# M3351 register map
File version: 1.0
Registers are 32-bit, read-write, reset 0x0 unless marked. A register's access mark holds for its fields unless they carry their own. Offsets are from the block's base; [hi:lo] are bit positions; {n}, {i} and the like mark numbered series.

## WWDT0 — WWDT Register Map
Base 0x40096000
Same registers: WWDT1 0x40098000, WWDT1_NS 0x50098000
0x00 WWDT_RLDCNT wo — WWDT Reload Counter Register
  [31:0] RLDCNT — WWDT Reload Counter Register. Writing 0x00005AA5 to this register will reload the WWDT counter value to 0x3F. Note: User can only write WWDT_RLDCNT register to reload WWDT counter value when current WWDT counter value between 0 and CMPDAT (WWDT_CTL[21:16]). If user writes WWDT_RLDCNT when current WWDT counter value is larger than CMPDAT, WWDT reset signal will be generated immediately.
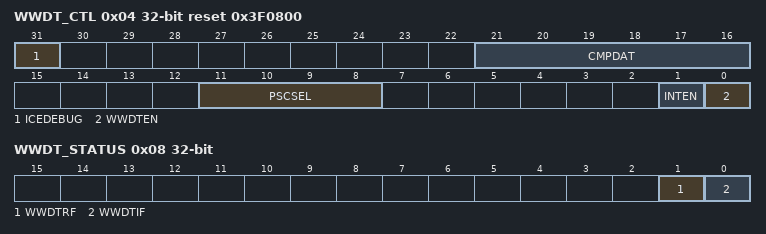
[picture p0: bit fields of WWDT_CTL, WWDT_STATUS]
0x04 WWDT_CTL reset 0x3F0800 — WWDT Control Register
  [31] ICEDEBUG — ICE Debug Mode Acknowledge Disable Bit. WWDT down counter will keep going no matter CPU is held by ICE or not.
    0=ICE debug mode acknowledgement effects WWDT counting; 1=ICE debug mode acknowledgement Disabled
  [21:16] CMPDAT — WWDT Window Compare. Set this register to adjust the valid reload window. Note: User can only write WWDT_RLDCNT register to reload WWDT counter value when current WWDT counter value between 0 and CMPDAT. If user writes WWDT_RLDCNT register when current WWDT counter value larger than CMPDAT, WWDT reset signal will generate immediately.
  [11:8] PSCSEL — WWDT Counter Prescale Period Selection
    0=Pre-scale is 1; Max time-out period is 1 * 64 * WWDT_CLK; 1=Pre-scale is 2; Max time-out period is 2 * 64 * WWDT_CLK; 2=Pre-scale is 4; Max time-out period is 4 * 64 * WWDT_CLK; 3=Pre-scale is 8; Max time-out period is 8 * 64 * WWDT_CLK; 4=Pre-scale is 16; Max time-out period is 16 * 64 * WWDT_CLK; 5=Pre-scale is 32; Max time-out period is 32 * 64 * WWDT_CLK; 6=Pre-scale is 64; Max time-out period is 64 * 64 * WWDT_CLK; 7=Pre-scale is 128; Max time-out period is 128 * 64 * WWDT_CLK; 8=Pre-scale is 192; Max time-out period is 192 * 64 * WWDT_CLK; 9=Pre-scale is 256; Max time-out period is 256 * 64 * WWDT_CLK; 10=Pre-scale is 384; Max time-out period is 384 * 64 * WWDT_CLK; 11=Pre-scale is 512; Max time-out period is 512 * 64 * WWDT_CLK; 12=Pre-scale is 768; Max time-out period is 768 * 64 * WWDT_CLK; 13=Pre-scale is 1024; Max time-out period is 1024 * 64 * WWDT_CLK; 14=Pre-scale is 1536; Max time-out period is 1536 * 64 * WWDT_CLK; 15=Pre-scale is 2048; Max time-out period is 2048 * 64 * WWDT_CLK
  [1] INTEN — WWDT Interrupt Enable Bit. If this bit is enabled, the WWDT counter compare match interrupt signal is generated and inform to CPU.
    0=WWDT counter compare match interrupt Disabled; 1=WWDT counter compare match interrupt Enabled
  [0] WWDTEN — WWDT Enable Bit
    0=WWDT counter is stopped; 1=Enable WWDT counter starts counting
0x08 WWDT_STATUS
  [1] WWDTRF — WWDT Timer-out Reset Flag. This bit indicates the system has been reset by WWDT time-out reset or not. Note: This bit is cleared by writing 1 to it.
    0=WWDT time-out reset did not occur; 1=WWDT time-out reset occurred
  [0] WWDTIF — WWDT Compare Match Interrupt Flag. This bit indicates the interrupt flag status of WWDT while WWDT counter value matches CMPDAT (WWDT_CTL[21:16]). Note: This bit is cleared by writing 1 to it.
    0=No effect; 1=WWDT counter value matches CMPDAT
0x0C WWDT_CNT ro reset 0x3F — WWDT Counter Value Register
  [5:0] CNTDAT — WWDT Counter Value. CNTDAT will be updated continuously to monitor 6-bit WWDT down counter value.

## DAC — DAC Register Map
Base 0x40047000
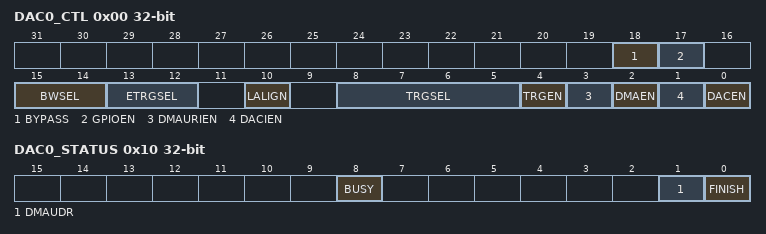
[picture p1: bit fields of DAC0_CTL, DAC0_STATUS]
0x00 DAC0_CTL — DAC0 Control Register
  [18] BYPASS — Bypass Buffer Mode
    0=Output voltage buffer Enabled; 1=Output voltage buffer Disabled
  [17] GPIOEN — GPIO Mode Enable Bit
    0=GPIO pin can output DAC0_OUT voltage; 1=GPIO pin can be used as other MFP
  [15:14] BWSEL — DAC Data Bit-width Selection
    0=Data is 12 bits; 1=Data is 8 bits
  [13:12] ETRGSEL — External Pin Trigger Selection
    0=Low level trigger; 1=High level trigger; 2=Falling edge trigger; 3=Rising edge trigger
  [10] LALIGN — DAC Data Left-aligned Enabled Bit
    0=Right alignment; 1=Left alignment
  [8:5] TRGSEL — Trigger Source Selection
    0=Software trigger; 1=External pin DAC0_ST trigger; {v}=Timer {v-2} trigger (v=2..5); 8=PWM0 trigger; 9=PWM1 trigger
  [4] TRGEN — Trigger Mode Enable Bit
    0=DAC event trigger mode Disabled; 1=DAC event trigger mode Enabled
  [3] DMAURIEN — DMA Under-run Interrupt Enable Bit
    0=DMA under-run interrupt Disabled; 1=DMA under-run interrupt Enabled
  [2] DMAEN — DMA Mode Enable Bit
    0=DMA mode Disabled; 1=DMA mode Enabled
  [1] DACIEN — DAC Interrupt Enable Bit
    0=DAC interrupt Disabled; 1=DAC interrupt Enabled
  [0] DACEN — DAC Enable Bit
    0=DAC Disabled; 1=DAC Enabled
0x04 DAC0_SWTRG — DAC0 Software Trigger Control Register
  [0] SWTRG — Software Trigger. Note: User writes this bit to generate one shot pulse and it is cleared to 0 by hardware automatically; reading this bit will always get 0.
    0=Software trigger Disabled; 1=Software trigger Enabled
0x08 DAC0_DAT — DAC0 Data Holding Register
  [15:0] DACDAT — DAC0 12-bit Holding Data. These bits are written by user software which specifies 12-bit conversion data for DAC output. The unused bits (DAC_DAT[3:0] in left-alignment mode and DAC_DAT[15:12] in right alignment mode) are ignored by DAC controller hardware. 12 bit left alignment: user has to load data into DAC_DAT[15:4] bits. 12 bit right alignment: user has to load data into DAC_DAT[11:0] bits.
0x0C DAC0_DATOUT ro — DAC0 Data Output Register
  [11:0] DATOUT — DAC 12-bit Output Data. These bits are current digital data for DAC output conversion. It is loaded from DAC_DAT register and user cannot write it directly.
0x10 DAC0_STATUS
  [8] BUSY — DAC Busy Flag (Read Only)
    0=DAC is ready for next conversion; 1=DAC is busy in conversion
  [1] DMAUDR — DMA Under-run Interrupt Flag. Note: User writes 1 to clear this bit.
    0=No DMA under-run error condition occurred; 1=DMA under-run error condition occurred
  [0] FINISH — DAC Conversion Complete Finish Flag. Note: This bit is set to 1 when conversion time counter counts to SETTLET. It is cleared to 0 when DAC starts a new conversion. User writes 1 to clear this bit to 0.
    0=DAC is in conversion state; 1=DAC conversion finish
0x14 DAC0_TCTL — DAC0 Timing Control Register
  [9:0] SETTLET — DAC Output Settling Time. User software needs to write appropriate value to these bits to meet DAC conversion settling time based on PCLK (APB clock) speed. For example, DAC controller clock speed is 72 MHz and DAC conversion settling time is 1 us, SETTLETvalue must be greater than 0x48.
